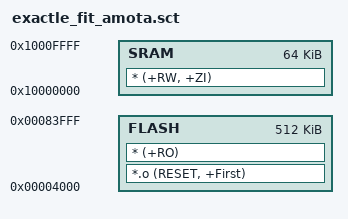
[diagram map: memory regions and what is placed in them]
;******************************************************************************
;
; exactle_fit_amota.sct
;
; Scatter file for Keil linker configuration.
;
;******************************************************************************

;******************************************************************************
;
; ${copyright}
;
; This is part of revision ${version} of the AmbiqSuite Development Package.
;
;******************************************************************************
LR_1 0x00004000
{
    FLASH 0x00004000 0x00080000
    {
        *.o (RESET, +First)
        * (+RO)
    }

    SRAM 0x10000000 0x00010000
    {
        * (+RW, +ZI)
    }
}

